# STM32F031x register map
File version: 1.0
Registers are 32-bit, read-write, reset 0x0 unless marked. A register's access mark holds for its fields unless they carry their own. Offsets are from the block's base; [hi:lo] are bit positions; {n}, {i} and the like mark numbered series.

## SYSCFG — System configuration controller
Base 0x40010000
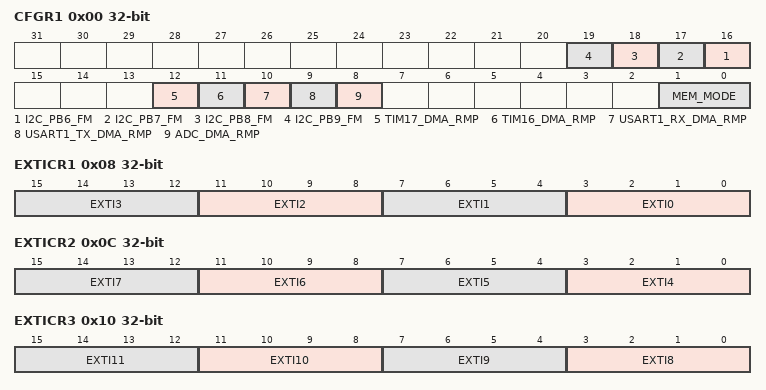
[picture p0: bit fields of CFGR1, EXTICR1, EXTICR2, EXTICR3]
0x00 CFGR1 — configuration register 1
  [n+10] I2C_PB{n}_FM (n=6..9) — Fast Mode Plus (FM+) driving capability activation bits.
  [12] TIM17_DMA_RMP — TIM17 DMA request remapping bit
  [11] TIM16_DMA_RMP — TIM16 DMA request remapping bit
  [10] USART1_RX_DMA_RMP — USART1_RX DMA request remapping bit
  [9] USART1_TX_DMA_RMP — USART1_TX DMA remapping bit
  [8] ADC_DMA_RMP — ADC DMA remapping bit
  [1:0] MEM_MODE — Memory mapping selection bits
0x08 EXTICR1 — external interrupt configuration register 1
  [4n+3:4n] EXTI{n} (n=0..3) — EXTI {n} configuration bits
0x0C EXTICR2 — external interrupt configuration register 2
  [4n-13:4n-16] EXTI{n} (n=4..7) — EXTI {n} configuration bits
0x10 EXTICR3 — external interrupt configuration register 3
  [4n-29:4n-32] EXTI{n} (n=8..11) — EXTI {n} configuration bits
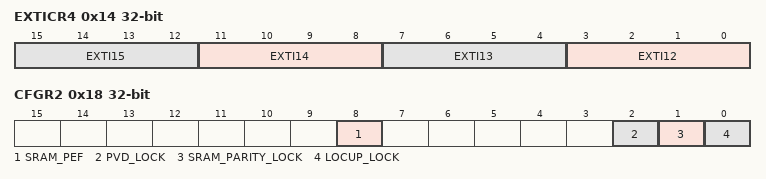
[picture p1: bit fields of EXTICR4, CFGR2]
0x14 EXTICR4 — external interrupt configuration register 4
  [4n-45:4n-48] EXTI{n} (n=12..15) — EXTI {n} configuration bits
0x18 CFGR2 — configuration register 2
  [8] SRAM_PEF — SRAM parity flag
  [2] PVD_LOCK — PVD lock enable bit
  [1] SRAM_PARITY_LOCK — SRAM parity lock bit
  [0] LOCUP_LOCK — Cortex-M0 LOCKUP bit enable bit

## ADC — Analog-to-digital converter
Base 0x40012400
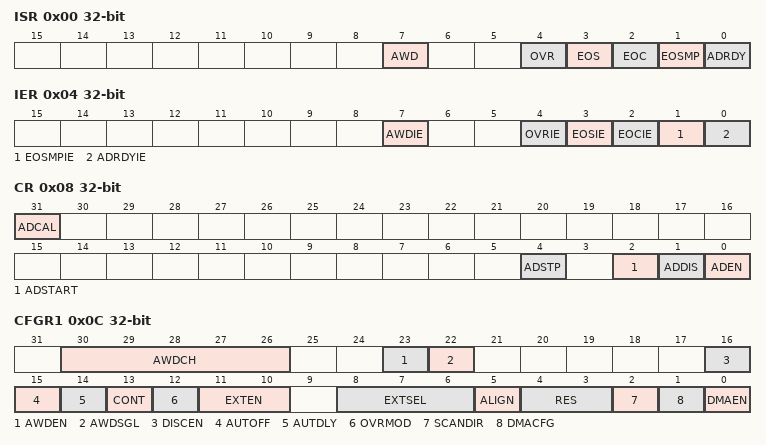
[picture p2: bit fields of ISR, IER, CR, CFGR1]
0x00 ISR — interrupt and status register
  [7] AWD — Analog watchdog flag
  [4] OVR — ADC overrun
  [3] EOS — End of sequence flag
  [2] EOC — End of conversion flag
  [1] EOSMP — End of sampling flag
  [0] ADRDY — ADC ready
0x04 IER — interrupt enable register
  [7] AWDIE — Analog watchdog interrupt enable
  [4] OVRIE — Overrun interrupt enable
  [3] EOSIE — End of conversion sequence interrupt enable
  [2] EOCIE — End of conversion interrupt enable
  [1] EOSMPIE — End of sampling flag interrupt enable
  [0] ADRDYIE — ADC ready interrupt enable
0x08 CR — control register
  [31] ADCAL — ADC calibration
  [4] ADSTP — ADC stop conversion command
  [2] ADSTART — ADC start conversion command
  [1] ADDIS — ADC disable command
  [0] ADEN — ADC enable command
0x0C CFGR1 — configuration register 1
  [30:26] AWDCH — Analog watchdog channel selection
  [23] AWDEN — Analog watchdog enable
  [22] AWDSGL — Enable the watchdog on a single channel or on all channels
  [16] DISCEN — Discontinuous mode
  [15] AUTOFF — Auto-off mode
  [14] AUTDLY — Auto-delayed conversion mode
  [13] CONT — Single / continuous conversion mode
  [12] OVRMOD — Overrun management mode
  [11:10] EXTEN — External trigger enable and polarity selection
  [8:6] EXTSEL — External trigger selection
  [5] ALIGN — Data alignment
  [4:3] RES — Data resolution
  [2] SCANDIR — Scan sequence direction
  [1] DMACFG — Direct memery access configuration
  [0] DMAEN — Direct memory access enable
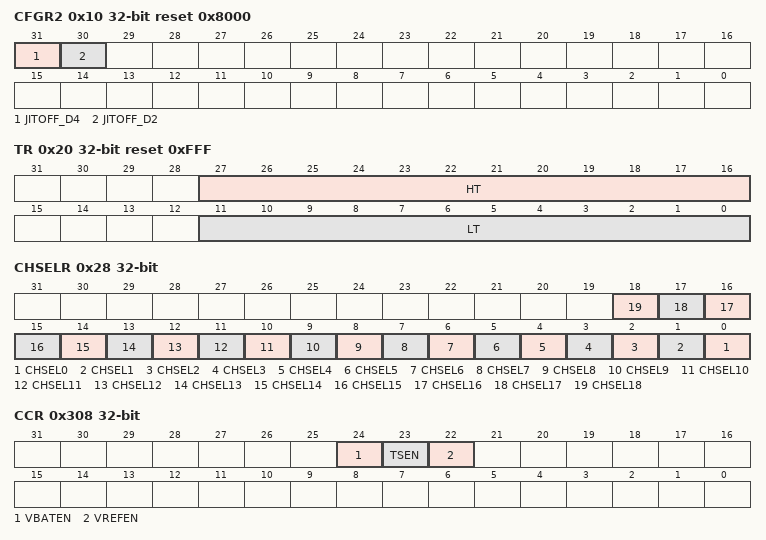
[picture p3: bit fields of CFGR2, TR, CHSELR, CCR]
0x10 CFGR2 reset 0x8000 — configuration register 2
  [31] JITOFF_D4, [30] JITOFF_D2
0x14 SMPR — sampling time register
  [2:0] SMPR — Sampling time selection
0x20 TR reset 0xFFF — watchdog threshold register
  [27:16] HT — Analog watchdog higher threshold
  [11:0] LT — Analog watchdog lower threshold
0x28 CHSELR — channel selection register
  [n] CHSEL{n} (n=0..18) — Channel-x selection
0x40 DR ro — data register
  [15:0] DATA — Converted data
0x308 CCR — common configuration register
  [24] VBATEN — VBAT enable
  [23] TSEN — Temperature sensor enable
  [22] VREFEN — Temperature sensor and VREFINT enable

## TIM16 — General-purpose-timers
Base 0x40014400
Same registers: TIM17 0x40014800
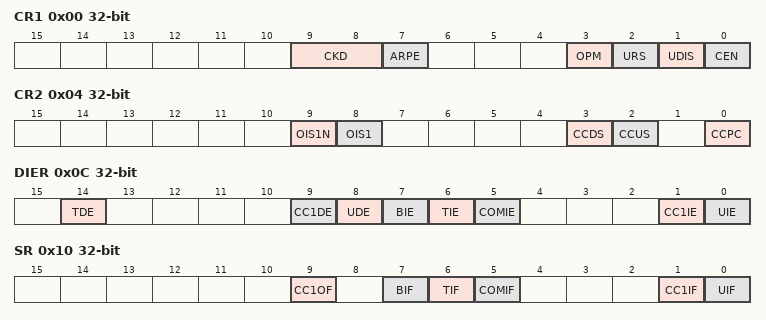
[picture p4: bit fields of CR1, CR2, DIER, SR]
0x00 CR1 — control register 1
  [9:8] CKD — Clock division
  [7] ARPE — Auto-reload preload enable
  [3] OPM — One-pulse mode
  [2] URS — Update request source
  [1] UDIS — Update disable
  [0] CEN — Counter enable
0x04 CR2 — control register 2
  [9] OIS1N — Output Idle state 1
  [8] OIS1 — Output Idle state 1
  [3] CCDS — Capture/compare DMA selection
  [2] CCUS — Capture/compare control update selection
  [0] CCPC — Capture/compare preloaded control
0x0C DIER — DMA/Interrupt enable register
  [14] TDE — Trigger DMA request enable
  [9] CC1DE — Capture/Compare 1 DMA request enable
  [8] UDE — Update DMA request enable
  [7] BIE — Break interrupt enable
  [6] TIE — Trigger interrupt enable
  [5] COMIE — COM interrupt enable
  [1] CC1IE — Capture/Compare 1 interrupt enable
  [0] UIE — Update interrupt enable
0x10 SR — status register
  [9] CC1OF — Capture/Compare 1 overcapture flag
  [7] BIF — Break interrupt flag
  [6] TIF — Trigger interrupt flag
  [5] COMIF — COM interrupt flag
  [1] CC1IF — Capture/compare 1 interrupt flag
  [0] UIF — Update interrupt flag
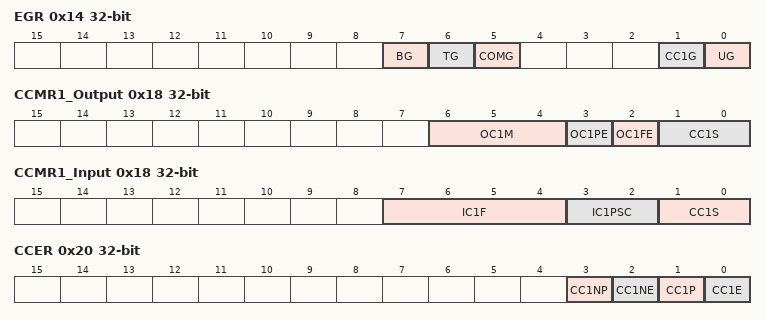
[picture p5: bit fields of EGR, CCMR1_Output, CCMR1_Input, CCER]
0x14 EGR wo — event generation register
  [7] BG — Break generation
  [6] TG — Trigger generation
  [5] COMG — Capture/Compare control update generation
  [1] CC1G — Capture/compare 1 generation
  [0] UG — Update generation
0x18 CCMR1_Output — capture/compare mode register (output mode)
  [6:4] OC1M — Output Compare 1 mode
  [3] OC1PE — Output Compare 1 preload enable
  [2] OC1FE — Output Compare 1 fast enable
  [1:0] CC1S — Capture/Compare 1 selection
0x18 CCMR1_Input (alternate view of CCMR1_Output) — capture/compare mode register 1 (input mode)
  [7:4] IC1F — Input capture 1 filter
  [3:2] IC1PSC — Input capture 1 prescaler
  [1:0] CC1S — Capture/Compare 1 selection
0x20 CCER — capture/compare enable register
  [3] CC1NP — Capture/Compare 1 output Polarity
  [2] CC1NE — Capture/Compare 1 complementary output enable
  [1] CC1P — Capture/Compare 1 output Polarity
  [0] CC1E — Capture/Compare 1 output enable
0x24 CNT — counter
  [15:0] CNT — counter value
0x28 PSC — prescaler
  [15:0] PSC — Prescaler value
0x2C ARR — auto-reload register
  [15:0] ARR — Auto-reload value
0x30 RCR — repetition counter register
  [7:0] REP — Repetition counter value
0x34 CCR1 — capture/compare register 1
  [15:0] CCR1 — Capture/Compare 1 value
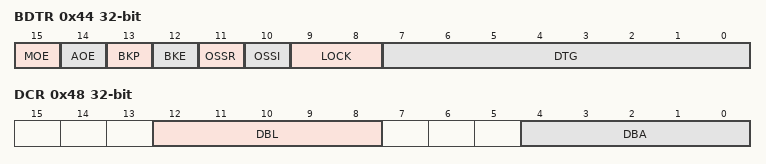
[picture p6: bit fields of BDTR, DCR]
0x44 BDTR — break and dead-time register
  [15] MOE — Main output enable
  [14] AOE — Automatic output enable
  [13] BKP — Break polarity
  [12] BKE — Break enable
  [11] OSSR — Off-state selection for Run mode
  [10] OSSI — Off-state selection for Idle mode
  [9:8] LOCK — Lock configuration
  [7:0] DTG — Dead-time generator setup
0x48 DCR — DMA control register
  [12:8] DBL — DMA burst length
  [4:0] DBA — DMA base address
0x4C DMAR — DMA address for full transfer
  [15:0] DMAB — DMA register for burst accesses
